VERSION ""

NS_ :

BS_:

BU_:

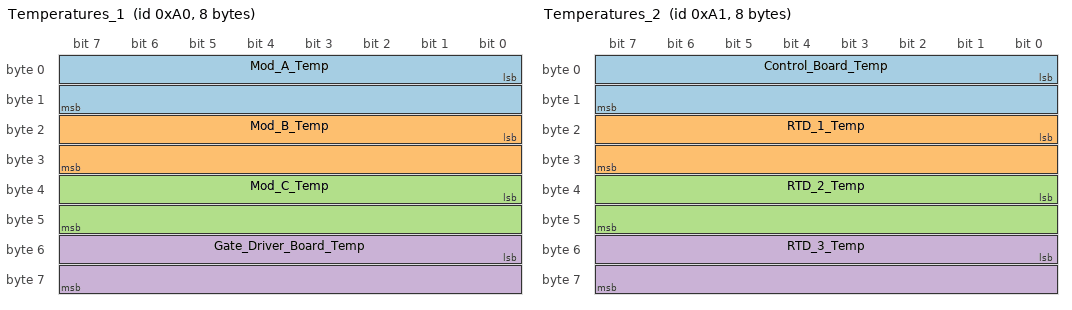
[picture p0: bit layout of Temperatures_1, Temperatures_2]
BO_ 160 Temperatures_1: 8 Vector__XXX
	SG_ Mod_A_Temp : 0|16@1- (0.1,0) [-3276.8|3276.7] "C" Vector__XXX
	SG_ Mod_B_Temp : 16|16@1- (0.1,0) [-3276.8|3276.7] "C" Vector__XXX
	SG_ Mod_C_Temp : 32|16@1- (0.1,0) [-3276.8|3276.7] "C" Vector__XXX
	SG_ Gate_Driver_Board_Temp : 48|16@1- (0.1,0) [-3276.8|3276.7] "C" Vector__XXX

BO_ 161 Temperatures_2: 8 Vector__XXX
	SG_ Control_Board_Temp : 0|16@1- (0.1,0) [-3276.8|3276.7] "C" Vector__XXX
	SG_ RTD_1_Temp : 16|16@1- (0.1,0) [-3276.8|3276.7] "C" Vector__XXX
	SG_ RTD_2_Temp : 32|16@1- (0.1,0) [-3276.8|3276.7] "C" Vector__XXX
	SG_ RTD_3_Temp : 48|16@1- (0.1,0) [-3276.8|3276.7] "C" Vector__XXX

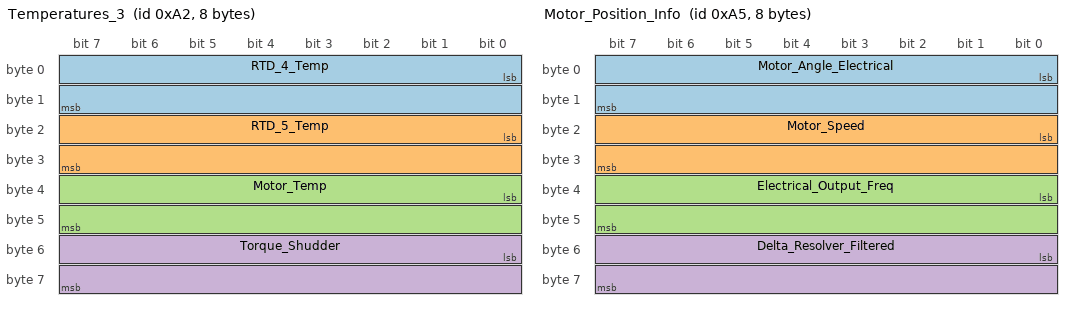
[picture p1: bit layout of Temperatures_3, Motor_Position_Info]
BO_ 162 Temperatures_3: 8 Vector__XXX
	SG_ RTD_4_Temp : 0|16@1- (0.1,0) [-3276.8|3276.7] "C" Vector__XXX
	SG_ RTD_5_Temp : 16|16@1- (0.1,0) [-3276.8|3276.7] "C" Vector__XXX
	SG_ Motor_Temp : 32|16@1- (0.1,0) [-3276.8|3276.7] "C" Vector__XXX
	SG_ Torque_Shudder : 48|16@1- (0.1,0) [-3276.8|3276.7] "N*m" Vector__XXX

BO_ 165 Motor_Position_Info: 8 Vector__XXX
	SG_ Motor_Angle_Electrical : 0|16@1- (0.1,0) [-359.9|359.9] "degrees" Vector__XXX
	SG_ Motor_Speed : 16|16@1- (0.1,0) [-32768|32767] "rpm" Vector__XXX
	SG_ Electrical_Output_Freq : 32|16@1- (0.1,0) [-3276.8|3276.7] "Hz" Vector__XXX
	SG_ Delta_Resolver_Filtered : 48|16@1- (0.1,0) [-359.9|359.9] "degrees" Vector__XXX

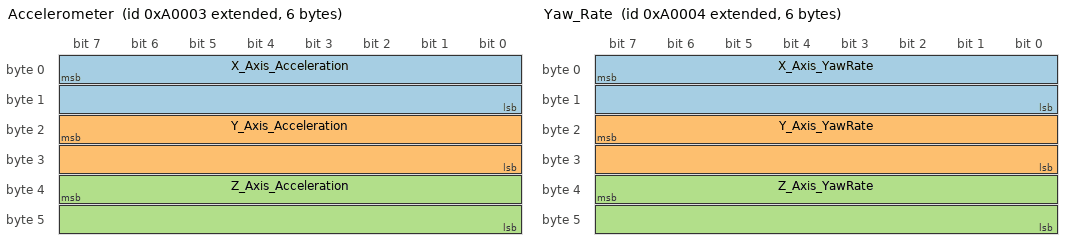
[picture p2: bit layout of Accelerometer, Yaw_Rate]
BO_ 2148139011 Accelerometer: 6 Vector__XXX
	SG_ X_Axis_Acceleration : 7|16@0- (0.000244141,0) [-8|8] "g" Vector__XXX
	SG_ Y_Axis_Acceleration : 23|16@0- (0.000244141,0) [-8|8] "g" Vector__XXX
	SG_ Z_Axis_Acceleration : 39|16@0- (0.000244141,0) [-8|8] "g" Vector__XXX

BO_ 2148139012 Yaw_Rate: 6 Vector__XXX
	SG_ X_Axis_YawRate : 7|16@0- (0.015258789,0) [-500|500] "deg/s" Vector__XXX
	SG_ Y_Axis_YawRate : 23|16@0- (0.015258789,0) [-500|500] "deg/s" Vector__XXX
	SG_ Z_Axis_YawRate : 39|16@0- (0.015258789,0) [-500|500] "deg/s" Vector__XXX

BA_DEF_ SG_  "SPN" INT 0 524287;
BA_DEF_ BO_  "VFrameFormat" ENUM  "StandardCAN","ExtendedCAN","reserved","J1939PG";
BA_DEF_  "DatabaseVersion" STRING ;
BA_DEF_  "BusType" STRING ;
BA_DEF_  "ProtocolType" STRING ;
BA_DEF_  "DatabaseCompiler" STRING ;
BA_DEF_DEF_  "SPN" 0;
BA_DEF_DEF_  "VFrameFormat" "J1939PG";
BA_DEF_DEF_  "DatabaseVersion" "DEMO PLUS";
BA_DEF_DEF_  "BusType" "";
BA_DEF_DEF_  "ProtocolType" "";
BA_DEF_DEF_  "DatabaseCompiler" "";
BA_ "ProtocolType" "J1939";
BA_ "BusType" "CAN";
BA_ "DatabaseCompiler" "CSS ELECTRONICS (WWW.CSSELECTRONICS.COM)";
BA_ "DatabaseVersion" "1.0.0";
BA_ "SPN" SG_ 2364540158 EngineSpeed 190;
